# netx90_app register map
File version: 1.0
CPU: CM4 r0p1, little endian, MPU, FPU, 4 interrupt priority bits, 78 interrupts
Registers are 32-bit, read-write, reset 0x0 unless marked. A register's access mark holds for its fields unless they carry their own. Offsets are from the block's base; [hi:lo] are bit positions; 'fields as' and 'values as' point back to an identical list.

## slave_firewall_ctrl
Base 0xFF401700
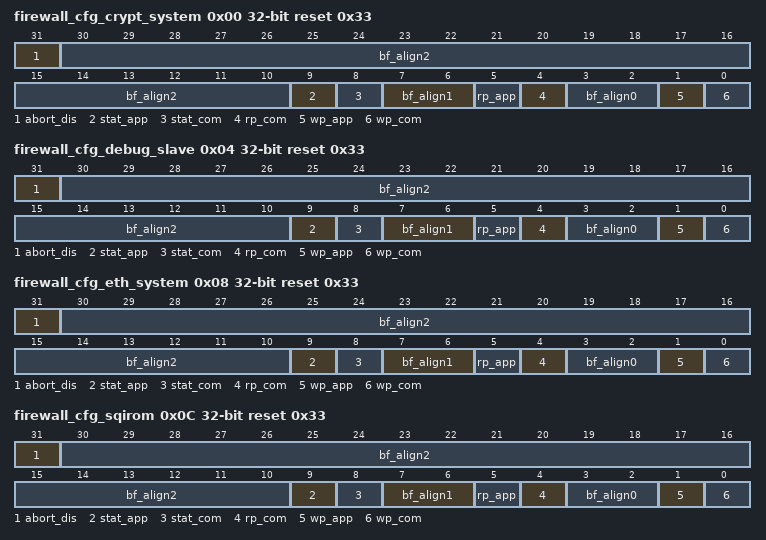
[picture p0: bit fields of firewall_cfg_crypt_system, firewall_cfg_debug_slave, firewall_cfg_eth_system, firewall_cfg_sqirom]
0x00 firewall_cfg_crypt_system reset 0x33 (reset mask 0x80000333) — Firewall configuration register for the crypt_system NETX AHB channel. Basic function: A denied access will generate an ERROR-response (abort). Masters which cannot handle aborts directly can generate an IRQ to their controlling master when they receive an abort (e.g. the DPM-master can generate an IRQ to its host or the DMA-controllers can generate an IRQ to the ARM-CPU). The firewall will no generate any IRQ by itself. A denied write access will be junked. A denied read access will return unpredictable data. Note: COM-side masters are: DPM0, DPM1, XC01, XPIC_COM, ARM_COM, DMAC_COM. APP-side masters are: IDPM_MASTER, XPIC_APP, ARM_APP, DMAC_APP. Other masters which cannot be filtered but globally disabled are: ADC_MASTER, IPC_MASTER, DEBUG_MASTER. Note: The configuration bits of this register can be locked to protect it from reconfiguration by ASIC_CTRL_COM.netx_lock.lock_firewall. The functionality of the status bits are not influenced by ASIC_CTRL_COM.netx_lock.lock_firewall.
  [31] abort_dis — disable abort-generation for denied accesses 1: no ERROR response for denied accesses (not recommended). 0: ERROR response for denied accesses (default)
  [30:10] bf_align2 — bitField alignment value for aeabi compatibility
  [9] stat_app — status for APP side masters, write '1' to clear.
  [8] stat_com — Firewall status for COM side masters, write '1' to clear. 1: an access of the COM side was denied 0: no denied accesses Note: Clearing the stat-bit by software has lower priority than setting by hardware. I.e. clearing a status bit while an access of the related is denied, will fail. Ensure that no access will be denied before clearing by stopping accessing master (e.g. DMAC which could perform long jobs with long bursts).
  [7:6] bf_align1 — bitField alignment value for aeabi compatibility
  [5] rp_app — read permission for APP side masters
  [4] rp_com — read permission for COM side masters 1: permit read access 0: deny read access
  [3:2] bf_align0 — bitField alignment value for aeabi compatibility
  [1] wp_app — write permission for APP side masters
  [0] wp_com — write permission for COM side masters 1: permit write access 0: deny write access
0x04 firewall_cfg_debug_slave reset 0x33 (reset mask 0x80000333) — Firewall configuration register for the debug_slave NETX AHB channel. See description of register firewall_cfg_crypt_system for details. Note: The configuration bits of this register can be locked to protect it from reconfiguration by ASIC_CTRL_COM.netx_lock.lock_firewall. The functionality of the status bits are not influenced by ASIC_CTRL_COM.netx_lock.lock_firewall.
  [31] abort_dis — disable abort-generation for denied accesses
  [30:10] bf_align2 — bitField alignment value for aeabi compatibility
  [9] stat_app — status for APP side masters, write '1' to clear.
  [8] stat_com — Firewall status for COM side masters, write '1' to clear.
  [7:6] bf_align1 — bitField alignment value for aeabi compatibility
  [5] rp_app — read permission for APP side masters
  [4] rp_com — read permission for COM side masters
  [3:2] bf_align0 — bitField alignment value for aeabi compatibility
  [1] wp_app — write permission for APP side masters
  [0] wp_com — write permission for COM side masters
0x08 firewall_cfg_eth_system reset 0x33 (reset mask 0x80000333) — Firewall configuration register for the eth_system NETX AHB channel. See description of register firewall_cfg_crypt_system for details. Note: The configuration bits of this register can be locked to protect it from reconfiguration by ASIC_CTRL_COM.netx_lock.lock_firewall. The functionality of the status bits are not influenced by ASIC_CTRL_COM.netx_lock.lock_firewall.
  fields as firewall_cfg_debug_slave
0x0C firewall_cfg_sqirom reset 0x33 (reset mask 0x80000333) — Firewall configuration register for the sqirom NETX AHB channel. See description of register firewall_cfg_crypt_system for details. Note: The configuration bits of this register can be locked to protect it from reconfiguration by ASIC_CTRL_COM.netx_lock.lock_firewall. The functionality of the status bits are not influenced by ASIC_CTRL_COM.netx_lock.lock_firewall.
  fields as firewall_cfg_debug_slave
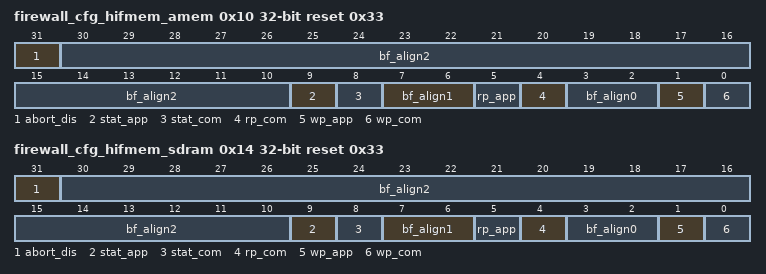
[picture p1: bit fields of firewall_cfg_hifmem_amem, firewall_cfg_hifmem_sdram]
0x10 firewall_cfg_hifmem_amem reset 0x33 (reset mask 0x80000333) — Firewall configuration register for the hifmem_amem NETX AHB channel. See description of register firewall_cfg_crypt_system for details. Note: The configuration bits of this register can be locked to protect it from reconfiguration by ASIC_CTRL_COM.netx_lock.lock_firewall. The functionality of the status bits are not influenced by ASIC_CTRL_COM.netx_lock.lock_firewall.
  fields as firewall_cfg_debug_slave
0x14 firewall_cfg_hifmem_sdram reset 0x33 (reset mask 0x80000333) — Firewall configuration register for the hifmem_sdram NETX AHB channel. See description of register firewall_cfg_crypt_system for details. Note: The configuration bits of this register can be locked to protect it from reconfiguration by ASIC_CTRL_COM.netx_lock.lock_firewall. The functionality of the status bits are not influenced by ASIC_CTRL_COM.netx_lock.lock_firewall.
  fields as firewall_cfg_debug_slave
